# R7FA2A2AD register map
Vendor: Renesas Electronics Corporation; Series: RA2A2; File version: 1.20.02
CPU: CM23 r1p0, little endian, MPU, no FPU, VTOR, 2 interrupt priority bits, 32 interrupts
Registers are 8-bit, read-write, reset 0x0 unless marked. A register's access mark holds for its fields unless they carry their own. Offsets are from the block's base; [hi:lo] are bit positions; {n}, {i} and the like mark numbered series; 'fields as' and 'values as' point back to an identical list.

## SYSC — System Control
Base 0x4001E000
0x0C SBYCR 16-bit — Standby Control Register
  [15] SSBY — Software Standby Mode Select
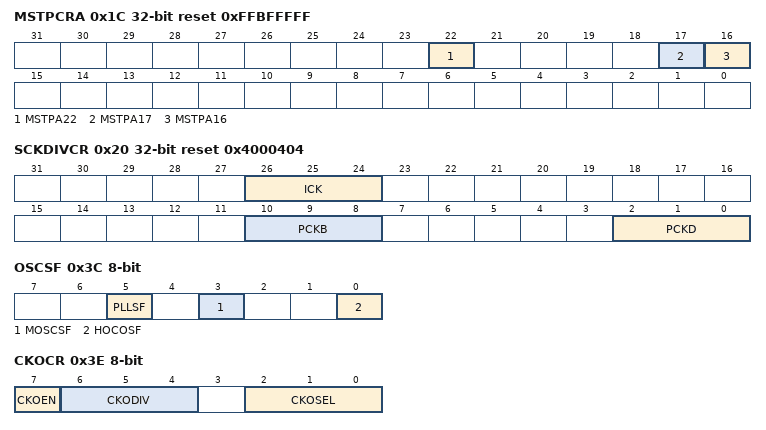
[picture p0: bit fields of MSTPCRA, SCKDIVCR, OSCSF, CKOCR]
0x1C MSTPCRA 32-bit reset 0xFFBFFFFF — Module Stop Control Register A
  [22] MSTPA22 — DTC Module Stop
  [17] MSTPA17 — Main Oscillation Stop Detection for SDADCCLK Module Stop
  [16] MSTPA16 — Sub Oscillation Stop Detection for SDADCCLK Module Stop
0x20 SCKDIVCR 32-bit reset 0x4000404 — System Clock Division Control Register
  [26:24] ICK — System Clock (ICLK) Select
  [10:8] PCKB — Peripheral Module Clock B (PCLKB) Select
  [2:0] PCKD — Peripheral Module Clock D (PCLKD) Select
0x26 SCKSCR reset 0x1 — System Clock Source Control Register
  [2:0] CKSEL — Clock Source Select
0x28 PLLCCR 16-bit reset 0x9E04 — PLL Clock Control Register
  [15:8] PLLMUL — PLL Frequency Multiplication Factor Select
0x2A PLLCR reset 0x1 — PLL Control Register
  [0] PLLSTP — PLL Stop Control
0x31 MEMWAIT — Memory Wait Cycle Control Register for Code Flash
  [0] MEMWAIT — Memory Wait Cycle Select for Code Flash
0x32 MOSCCR reset 0x1 — Main Clock Oscillator Control Register
  [0] MOSTP — Main Clock Oscillator Stop
0x36 HOCOCR (reset mask 0xFE) — High,Speed On,Chip Oscillator Control Register
  [0] HCSTP — HOCO Stop
0x38 MOCOCR — Middle,Speed On,Chip Oscillator Control Register
  [0] MCSTP — MOCO Stop
0x3C OSCSF ro (reset mask 0xFE) — Oscillation Stabilization Flag Register
  [5] PLLSF — PLL Clock Oscillation Stabilization Flag
  [3] MOSCSF — Main Clock Oscillation Stabilization Flag
  [0] HOCOSF — HOCO Clock Oscillation Stabilization Flag
0x3E CKOCR — Clock Out Control Register
  [7] CKOEN — Clock Out Enable
  [6:4] CKODIV — Clock Output Frequency Division Ratio
  [2:0] CKOSEL — Clock Out Source Select
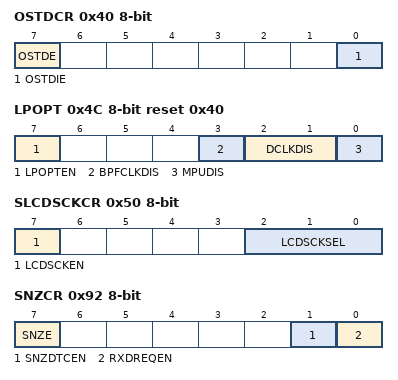
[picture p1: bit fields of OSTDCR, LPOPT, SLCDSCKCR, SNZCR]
0x40 OSTDCR — Oscillation Stop Detection Control Register
  [7] OSTDE — Oscillation Stop Detection Function Enable
  [0] OSTDIE — Oscillation Stop Detection Interrupt Enable
0x41 OSTDSR — Oscillation Stop Detection Status Register
  [0] OSTDF — Oscillation Stop Detection Flag
0x4C LPOPT reset 0x40 — Lower Power Operation Control Register
  [7] LPOPTEN — Lower Power Operation Enable
  [3] BPFCLKDIS — BPF Clock Disable Control
  [2:1] DCLKDIS — Debug Clock Disable Control
  [0] MPUDIS — MPU Clock Disable Control
0x50 SLCDSCKCR — Segment LCD Source Clock Control Register
  [7] LCDSCKEN — LCD Source Clock Out Enable
  [2:0] LCDSCKSEL — LCD Source Clock (LCDSRCCLK) Select
0x61 MOCOUTCR — MOCO User Trimming Control Register
  [7:0] MOCOUTRM — MOCO User Trimming
0x62 HOCOUTCR — HOCO User Trimming Control Register
  [7:0] HOCOUTRM — HOCO User Trimming
0x92 SNZCR — Snooze Control Register
  [7] SNZE — Snooze mode Enable
  [1] SNZDTCEN — DTC Enable in Snooze mode
  [0] RXDREQEN — RXD0 Snooze Request Enable
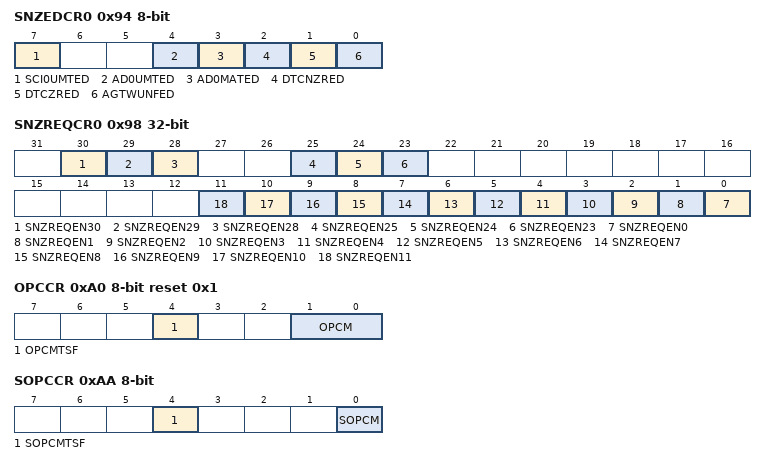
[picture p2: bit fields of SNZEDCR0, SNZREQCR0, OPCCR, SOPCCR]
0x94 SNZEDCR0 — Snooze End Control Register 0
  [7] SCI0UMTED — SCI0 Address Mismatch Snooze End Enable
  [4] AD0UMTED — ADC12 Compare Mismatch Snooze End Enable
  [3] AD0MATED — ADC12 Compare Match Snooze End Enable
  [2] DTCNZRED — Not Last DTC Transmission Completion Snooze End Enable
  [1] DTCZRED — Last DTC Transmission Completion Snooze End Enable
  [0] AGTWUNFED — AGTW1 Underflow Snooze End Enable
0x98 SNZREQCR0 32-bit — Snooze Request Control Register 0
  [30] SNZREQEN30 — Enable AGTW1 Compare Match B Snooze Request
  [29] SNZREQEN29 — Enable AGTW1 Compare Match A Snooze Request
  [28] SNZREQEN28 — Enable AGTW1 Underflow Snooze Request
  [25] SNZREQEN25 — Enable RTC Period Snooze Request
  [24] SNZREQEN24 — Enable RTC Alarm 0 Snooze Request
  [23] SNZREQEN23 — Enable RTC Alarm 1 Snooze Request
  [n] SNZREQEN{n} (n=0..11) — Enable IRQ{n} Pin Snooze Request
0x9F PSMCR — Power Save Memory Control Register
  [1:0] PSMC — Power Save Memory Control
0xA0 OPCCR reset 0x1 — Operating Power Control Register
  [4] OPCMTSF ro — Operating Power Control Mode Transition Status Flag
  [1:0] OPCM — Operating Power Control Mode Select
0xA2 MOSCWTCR reset 0x5 — Main Clock Oscillator Wait Control Register
  [3:0] MSTS — Main Clock Oscillator Wait Time Setting
0xA5 HOCOWTCR reset 0x5 — High,Speed On,Chip Oscillator Wait Control Register
  [2:0] HSTS — HOCO Wait Time Setting
0xAA SOPCCR — Sub Operating Power Control Register
  [4] SOPCMTSF ro — Operating Power Control Mode Transition Status Flag
  [0] SOPCM — Sub Operating Power Control Mode Select
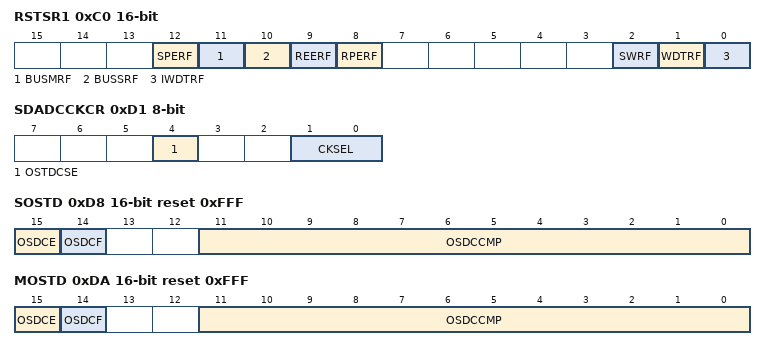
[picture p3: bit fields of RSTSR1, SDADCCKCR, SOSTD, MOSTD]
0xC0 RSTSR1 16-bit (reset mask 0xE0F8) — Reset Status Register 1
  [12] SPERF — CPU Stack Pointer Error Reset Detect Flag
  [11] BUSMRF — Bus Master MPU Error Reset Detect Flag
  [10] BUSSRF — Bus Slave MPU Error Reset Detect Flag
  [9] REERF — SRAM ECC Error Reset Detect Flag
  [8] RPERF — SRAM Parity Error Reset Detect Flag
  [2] SWRF — Software Reset Detect Flag
  [1] WDTRF — Watchdog Timer Reset Detect Flag
  [0] IWDTRF — Independent Watchdog Timer Reset Detect Flag
0xD1 SDADCCKCR — 24-bit Sigma,delta A/D Converter Clock Control Register
  [4] OSTDCSE — Clock Switch Enable for Oscillation Stop Detected
  [1:0] CKSEL — 24-bit Sigma,delta A/D Converter Clock Select
0xD8 SOSTD 16-bit reset 0xFFF — Sub Clock Oscillation Stop Detection Control Register
  [15] OSDCE — Control of Oscillation Stop Detector Operation
  [14] OSDCF ro — Status of Oscillation Stop Detector Operation
  [11:0] OSDCCMP — Oscillation Stop Detection Time
0xDA MOSTD 16-bit reset 0xFFF — Main Oscillation Stop Detection Control Register
  fields as SOSTD
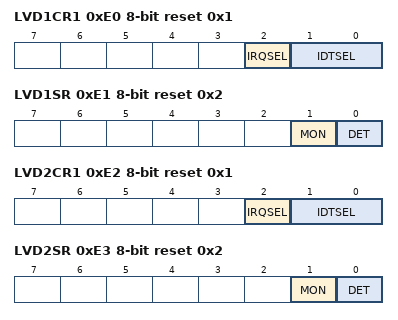
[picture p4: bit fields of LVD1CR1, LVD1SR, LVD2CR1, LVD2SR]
0xE0 LVD1CR1 reset 0x1 — Voltage Monitor 1 Circuit Control Register
  [2] IRQSEL — Voltage Monitor 1 Interrupt Type Select
  [1:0] IDTSEL — Voltage Monitor 1 Interrupt Generation Condition Select
0xE1 LVD1SR reset 0x2 — Voltage Monitor 1 Circuit Status Register
  [1] MON ro — Voltage Monitor 1 Signal Monitor Flag
  [0] DET — Voltage Monitor 1 Voltage Variation Detection Flag
0xE2 LVD2CR1 reset 0x1 — Voltage Monitor 2 Circuit Control Register 1
  [2] IRQSEL — Voltage Monitor 2 Interrupt Type Select
  [1:0] IDTSEL — Voltage Monitor 2 Interrupt Generation Condition Select
0xE3 LVD2SR reset 0x2 — Voltage Monitor 2 Circuit Status Register
  [1] MON ro — Voltage Monitor 2 Signal Monitor Flag
  [0] DET — Voltage Monitor 2 Voltage Variation Detection Flag
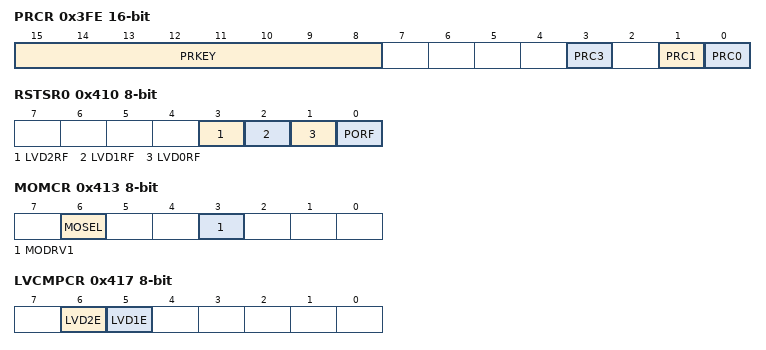
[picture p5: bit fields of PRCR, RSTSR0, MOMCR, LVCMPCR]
0x3FE PRCR 16-bit — Protect Register
  [15:8] PRKEY wo — PRC Key Code
  [3] PRC3 — Enable writing to the registers related to the LVD
  [1] PRC1 — Enable writing to the registers related to the low power modes
  [0] PRC0 — Enable writing to the registers related to the clock generation circuit
0x40E SYOCDCR — System Control OCD Control Register
  [7] DBGEN — Debugger Enable bit
0x410 RSTSR0 (reset mask 0xF0) — Reset Status Register 0
  [3] LVD2RF — Voltage Monitor 2 Reset Detect Flag
  [2] LVD1RF — Voltage Monitor 1 Reset Detect Flag
  [1] LVD0RF — Voltage Monitor 0 Reset Detect Flag
  [0] PORF — Power,On Reset Detect Flag
0x411 RSTSR2 (reset mask 0xFE) — Reset Status Register 2
  [0] CWSF — Cold/Warm Start Determination Flag
0x413 MOMCR — Main Clock Oscillator Mode Oscillation Control Register
  [6] MOSEL — Main Clock Oscillator Switching
  [3] MODRV1 — Main Clock Oscillator Drive Capability 1 Switching
0x417 LVCMPCR — Voltage Monitor Circuit Control Register
  [6] LVD2E — Voltage Detection 2 Enable
  [5] LVD1E — Voltage Detection 1 Enable
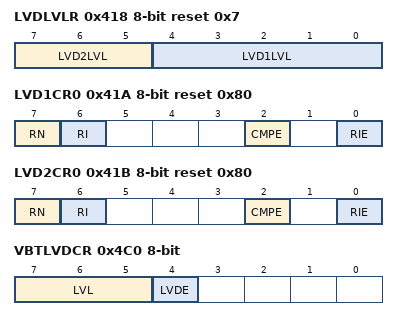
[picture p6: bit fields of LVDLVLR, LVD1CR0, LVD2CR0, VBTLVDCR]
0x418 LVDLVLR reset 0x7 — Voltage Detection Level Select Register
  [7:5] LVD2LVL — Voltage Detection 2 Level Select (Standard voltage during fall in voltage)
  [4:0] LVD1LVL — Voltage Detection 1 Level Select (Standard voltage during fall in voltage)
0x41A LVD1CR0 reset 0x80 — Voltage Monitor 1 Circuit Control Register 0
  [7] RN — Voltage Monitor 1 Reset Negate Select
  [6] RI — Voltage Monitor 1 Circuit Mode Select
  [2] CMPE — Voltage Monitor 1 Circuit Comparison Result Output Enable
  [0] RIE — Voltage Monitor 1 Interrupt/Reset Enable
0x41B LVD2CR0 reset 0x80 — Voltage Monitor 2 Circuit Control Register 0
  [7] RN — Voltage Monitor 2 Reset Negate Select
  [6] RI — Voltage Monitor 2 Circuit Mode Select
  [2] CMPE — Voltage Monitor 2 Circuit Comparison Result Output Enable
  [0] RIE — Voltage Monitor 2 Interrupt/Reset Enable
0x480 SOSCCR reset 0x1 — Sub,Clock Oscillator Control Register
  [0] SOSTP — Sub Clock Oscillator Stop
0x481 SOMCR — Sub,Clock Oscillator Mode Control Register
  [1:0] SODRV — Sub,Clock Oscillator Drive Capability Switching
0x482 SOMRG — Sub,Clock Oscillator Margin Check Register
  [1:0] SOSCMRG — Sub Clock Oscillator Margin Check Switching
0x490 LOCOCR — Low,Speed On,Chip Oscillator Control Register
  [0] LCSTP — LOCO Stop
0x492 LOCOUTCR — LOCO User Trimming Control Register
  [7:0] LOCOUTRM — LOCO User Trimming
0x4C0 VBTLVDCR — EXLVDVBAT Circuit Control Register
  [7:5] LVL — EXLVDVBAT Pin Low Voltage Detect Level Select
  [4] LVDE — EXLVDVBAT Pin Low Voltage Detect Enable
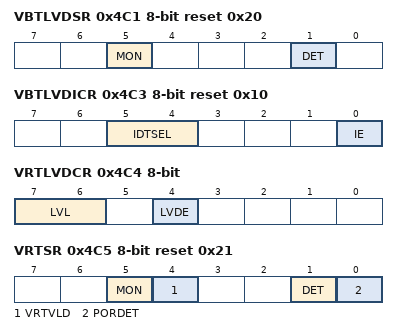
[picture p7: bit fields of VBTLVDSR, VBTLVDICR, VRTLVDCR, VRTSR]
0x4C1 VBTLVDSR reset 0x20 — EXLVDVBAT Circuit Status Register
  [5] MON ro — EXLVDVBAT Pin Low Voltage Monitor Flag
  [1] DET — EXLVDVBAT Pin Low Voltage Detect Flag
0x4C2 VBTCMPCR — EXLVDVBAT Comparator Control Register
  [0] CMPE — EXLVDVBAT Pin Low Voltage Detect Circuit Output Enable
0x4C3 VBTLVDICR reset 0x10 — EXLVDVBAT Pin Low Voltage Detect Interrupt Control Register
  [5:4] IDTSEL — EXLVDVBAT Pin Low Voltage Detect Interrupt Generation Condition Select
  [0] IE — EXLVDVBAT Pin Low Voltage Detect Interrupt Enable
0x4C4 VRTLVDCR — LVDVRTC Circuit Control Register
  [7:6] LVL — VRTC Pin Low Voltage Detect Level Select
  [4] LVDE — VRTC Pin Low Voltage Detect Enable
0x4C5 VRTSR reset 0x21 — VRTC Status Register
  [5] MON ro — VRTC Signal Monitor Flag
  [4] VRTVLD ro — VRTC,domain Valid
  [1] DET — VRTC Voltage Variation Detection Flag
  [0] PORDET — VRTC,domain Power,on Reset Detect Flag
0x4C6 VRTCMPCR — VRTC Comparator Control Register
  [0] CMPE — VRTC Pin Low Voltage Detect Circuit Output Enable
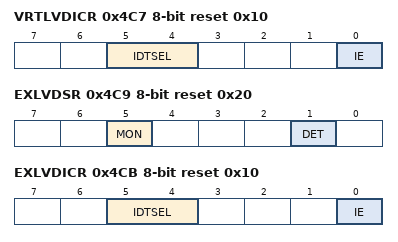
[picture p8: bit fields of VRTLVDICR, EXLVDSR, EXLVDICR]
0x4C7 VRTLVDICR reset 0x10 — VRTC Pin Low Voltage Detect Interrupt Control Register
  [5:4] IDTSEL — VRTC Pin Low Voltage Detect Interrupt Generation Condition Select
  [0] IE — VRTC Pin Low Voltage Detect Interrupt Enable
0x4C8 EXLVDCR — EXLVD Circuit Control Register
  [4] LVDE — EXLVD Pin Low Voltage Detect Enable
0x4C9 EXLVDSR reset 0x20 — EXLVD Circuit Status Register
  [5] MON ro — EXLVD pin Low Voltage Monitor Flag
  [1] DET — EXLVD pin Low Voltage Detect Flag
0x4CA EXLVDCMPCR — EXLVD Comparator Control Register
  [0] CMPE — EXLVD Pin Low Voltage Detect Circuit Output Enable
0x4CB EXLVDICR reset 0x10 — EXLVD Pin Low Voltage Detect Interrupt Control Register
  [5:4] IDTSEL — EXLVD Pin Low Voltage Detect Interrupt Generation Condition Select
  [0] IE — EXLVD Pin Low Voltage Detect Interrupt Enable
